# M0519AE_v1 register map
File version: 1.0
Registers are 32-bit, read-write, reset 0x0 unless marked. A register's access mark holds for its fields unless they carry their own. Offsets are from the block's base; [hi:lo] are bit positions; 'fields as' and 'values as' point back to an identical list.

## EPWM0 — EPWM Register Map
Base 0x40190000
Same registers: EPWM1 0x40194000
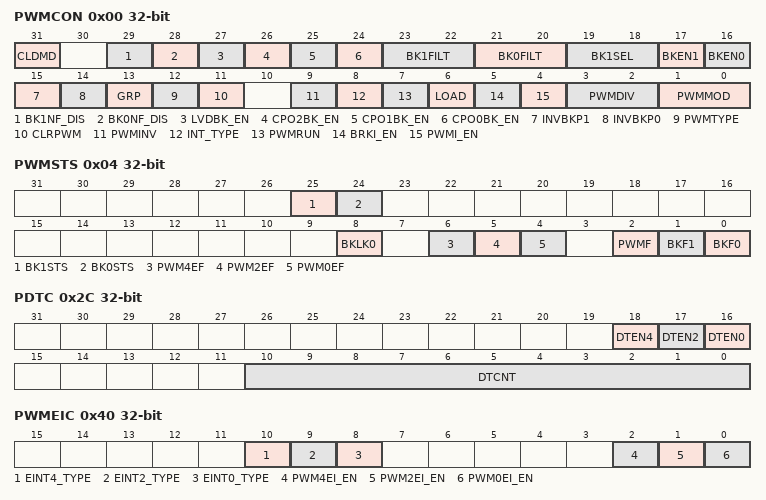
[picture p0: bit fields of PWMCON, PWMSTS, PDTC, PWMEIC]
0x00 PWMCON — EPWM Control Register
  [31] CLDMD — Center Reload Mode Enable Bit. This bit only works when EPWM operating in Center-aligned mode.
    0=EPWM reload duty register at the period point of PWM counter; 1=EPWM reload duty register at the center point of PWM counter
  [29] BK1NF_DIS — PWM Brake 1 Noise Filter Disable Bit
    0=Noise filter of PWM Brake 1 Enabled; 1=Noise filter of PWM Brake 1 Disabled
  [28] BK0NF_DIS — PWM Brake 0 Noise Filter Disable Bit
    0=Noise filter of PWM Brake 0 Enabled; 1=Noise filter of PWM Brake 0 Disabled
  [27] LVDBK_EN — Low-level Detection Trigger PWM Brake Function 1 Enable Bit
    0=Brake Function 1 triggered by Low-level detection Disabled; 1=Brake Function 1 triggered by Low-level detection Enabled
  [26] CPO2BK_EN — ACMP2 Digital Output As Brake 0 Source Enable Bit
    0=CO2 (ACMPSR[10]) as one brake source in Brake 0 Disabled; 1=CO2 (ACMPSR[10]) as one brake source in Brake 0 Enabled
  [25] CPO1BK_EN — ACMP1 Digital Output As Brake 0 Source Enable Bit
    0=CO1 (ACMPSR[9]) as one brake source in Brake 0 Disabled; 1=CO1 (ACMPSR[9]) as one brake source in Brake 0 Enabled
  [24] CPO0BK_EN — ACMP0 Digital Output As Brake0 Source Enable Bit
    0=CO0 (ACMPSR[8]) as one brake source in Brake 0 Disabled; 1=CO0 (ACMPSR[8]) as one brake source in Brake 0 Enabled
  [23:22] BK1FILT — Brake 1 (BKPx1 Pin) Edge Detector Filter Clock Selection
    0=filter clock is HCLK; 1=filter clock is HCLK/2; 2=filter clock is HCLK/4; 3=filter clock is HCLK/16
  [21:20] BK0FILT — Brake 0 (BKPx0 Pin) Edge Detector Filter Clock Selection
    values as BK1FILT
  [19:18] BK1SEL — Brake Function 1 Source Selection
    0=brake signal is from external pin EPWMx_BRAKE1 (x=0~1 for unit0~1); 1=brake signal is from analog comparator 0 output CO0 (ACMPSR[8]); 2=brake signal is from analog comparator 1 output CO1 (ACMPSR[9]); 3=brake signal is from analog comparator 2 output CO2 (ACMPSR[10])
  [17] BKEN1 — BRAKE1 Pin Trigger Brake Function 1 Enable Bit
    0=PWMx brake function 1 Disabled; 1=PWMx brake function 1 Enabled
  [16] BKEN0 — BRAKE0 Pin Trigger Brake Function 0 Enable Bit
    0=PWMx brake function 0 Disabled; 1=PWMx brake function 0 Enabled
  [15] INVBKP1 — Inverse Brake 1 Pin State
    0=The state of pin EPWMx_BRAKE1 is passed to the negative edge detector; 1=The inversed state of pin EPWMx_BRAKE1 is passed to the negative edge detector
  [14] INVBKP0 — Inverse Brake 0 Pin State
    0=The state of pin EPWMx_BRAKE0 is passed to the negative edge detector; 1=The inversed state of pin EPWMx_BRAKE0 is passed to the negative edge detector
  [13] GRP — Group Bit
    0=The signals timing of PWM_CH0, PWM_CH2 and PWM_CH4 are independent; 1=Unify the signals timing of PWM_CH0, PWM_CH2 and PWM_CH4 in the same phase which is controlled by PWM_CH0
  [12] PWMTYPE — PWM Aligned Type Selection Bit
    0=Edge-aligned type; 1=Center-aligned type
  [11] CLRPWM — Clear PWM Counter Control Bit. Note: It is automatically cleared by hardware.
    0=Ignored; 1=Clear 16-bit PWM counter to 0000H
  [9] PWMINV — Inverse PWM Comparator Output. When PWMINV is set to high the PWM comparator output signals will be inversed, therefore the PWM Duty (in percentage) is changed to (1-Duty) before PWMINV is set to high.
    0=Not inverse PWM comparator output; 1=Inverse PWM comparator output
  [8] INT_TYPE — PWM Interrupt Type Selection Bit. Note: This bit is effective when PWM is in Center-aligned mode only.
    0=PWMF will be set if PWM counter underflow; 1=PWMF will be set if PWM counter matches PWMP register
  [7] PWMRUN — Start PWMRUN Control Bit
    0=The PWM stops running; 1=The PWM counter starts running
  [6] LOAD — Reload PWM Period Registers (PWMP) and PWM Duty Registers (PWM0~4) Control Bit. Note: This bit is written by software, cleared by hardware, and always read as 0.
    0=No action if written with 0. The value of PWM period register (PWMP) and PWM duty registers (PWM0~PWM4) are not loaded to PWM counter and Comparator registers; 1=Hardware will update the value of PWM period register (PWMP) and PWM duty registers (PWM0~PWM4) to PWM Counter and Comparator register at the time of PWM Counter matches PWMP in Edge- and Center-aligned modes or at the time of PWM Counter down counts with underflow in Center-aligned mode
  [5] BRKI_EN — Brake0 and Brak1 Interrupt Enable Bit
    0=Flags BKF0 (PWMSTS[0]) and BKF1 (PWMSTS[1]) Disabled to trigger PWM interrupt; 1=Flags BKF0 (PWMSTS[0]) and BKF1 (PWMSTS[1]) Enabled to trigger PWM interrupt
  [4] PWMI_EN — PWM Interrupt Enable Bit
    0=Flag PWMF (PWMSTS[2]) Disabled to trigger PWM interrupt; 1=Flag PWMF (PWMSTS[2]) Enabled to trigger PWM interrupt
  [3:2] PWMDIV — PWM Clock Pre-divider Selection
    0=PWM clock is EPWMx_CLK; 1=PWM clock is EPWMx_CLK/2; 2=PWM clock is EPWMx_CLK/4; 3=PWM clock is EPWMx_CLK/16
  [1:0] PWMMOD — PWM Mode Selection
    0=PWM mode is independent mode; 1=PWM mode is pair/complementary mode; 2=PWM mode is synchronized mode
0x04 PWMSTS — EPWM Status Register
  [25] BK1STS ro — Brake 1 Status (Read Only)
    0=PWM had been out of Brake 1 state; 1=PWM is in Brake 1 state
  [24] BK0STS ro — Brake 0 Status (Read Only)
    0=PWM had been out of Brake 0 state; 1=PWM is in Brake 0 state
  [8] BKLK0 — PWM Brake 0 Locked. Note: This bit must be cleared by writing 1 to itself through software.
    0=Brake 0 state is released; 1=When PWM Brake detects a falling signal at EPWMx_BRAKE0, x=0, 1. This flag will be set to high to indicate the Brake 0 state is locked
  [6] PWM4EF — PWM Channel 4 Edge Flag. Note: This bit must be cleared by writing 1 to itself through software.
    0=PWM_CH4 not toggled; 1=Hardware will set this flag to high at the time of PWM_CH4 rising or falling. If EINT4_TYPE (PWMEIC[10]) = 0, this bit is set when PWM_CH4 falling is detected. If EINT4_TYPE (PWMEIC[10]) = 1, this bit is set when PWM_CH4 rising is detected
  [5] PWM2EF — PWM Channel 2 Edge Flag. Note: This bit must be cleared by writing 1 to itself through software.
    0=PWM_CH2 not toggled; 1=Hardware will set this flag to high at the time of PWM_CH2 rising or falling. If EINT2_TYPE (PWMEIC[9]) = 0, this bit is set when PWM_CH2 falling is detected. If EINT2_TYPE (PWMEIC[9]) = 1, this bit is set when PWM_CH2 rising is detected
  [4] PWM0EF — PWM Channel 0 Edge Flag. Note: This bit must be cleared by writing 1 to itself through software.
    0=PWM_CH0 not toggled; 1=Hardware will set this flag to high at the time of PWM_CH0 rising or falling. If EINT0_TYPE (PWMEIC[8]) = 0, this bit is set when PWM_CH0 falling is detected. If EINT0_TYPE (PWMEIC[8]) = 1, this bit is set when PWM_CH0 rising is detected
  [2] PWMF — PWM Period Flag. Note: This bit must be cleared by writing 1 to itself through software.
    0=The PWM Counter has not up counted to the value of PWMP or down counted with underflow; 1=Hardware will set this flag to high at the time of PWM Counter matches PWMP in Edge- and Center-aligned modes or at the time of PWM Counter down counts with underflow in Center-aligned mode
  [1] BKF1 — PWM Brake1 Flag. Note: This bit must be cleared by writing 1 to itself through software.
    0=PWM Brake 1 is able to poll falling signal at EPWMx_BRAKE1, x=0, 1 and has not recognized any one; 1=When PWM Brake 1 detects a falling signal at pin EPWMx_BRAKE1, x=0, 1, this flag will be set to high
  [0] BKF0 — PWM Brake0 Flag. Note: This bit must be cleared by writing 1 to itself through software.
    0=PWM Brake 0 is able to poll falling signal at EPWMx_BRAKE0, x=0, 1 and has not recognized any one; 1=When PWM Brake 0 detects a falling signal at EPWMx_BRAKE0, x=0, 1, this flag will be set to high
0x08 PWMP — EPWM Period Register
  [15:0] PWMP — PWM Period Register. Edge-aligned:
0x0C PWM0 — EPWM PWM0 Duty Register
  [15:0] PWM_Duty — PWM Duty Register. Edge-aligned:
0x10 PWM2 — EPWM PWM2 Duty Register
  [15:0] PWM_Duty — PWM Duty Register. Edge-aligned:
0x14 PWM4 — EPWM PWM4 Duty Register
  [15:0] PWM_Duty — PWM Duty Register. Edge-aligned:
0x18 PMSKE — EPWM Mask Mode Enable Register
  [5:0] PMSKE — PWM Mask Enable Bits. The PWM generator signal will be masked when this bit is enabled. The corresponding PWM channel n will be output with PMSKD[n] data.
    0=PWM generator signal is output to next stage; 1=PWM generator signal is masked and PMSKD[n] is output to next stage, n = 0~5
0x1C PMSKD — EPWM Mask Mode Data Register
  [5:0] PMSKD — PWM Mask Data Bit
    0=Output logic low to PWM_CHn; 1=Output logic high to PWM_CHn
0x2C PDTC — EPWM Dead-time Control Register
  [18] DTEN4 — Enable Dead-time Insertion for PWMx Pair (PWM_CH4, PWM_CH5). Dead-time insertion is only active when this pair of complementary PWM is enabled. If dead-time insertion is inactive, the outputs of pin pair are complementary without any delay.
    0=Dead-time insertion Disabled on the pin pair (PWM_CH4, PWM_CH5); 1=Dead-time insertion Enabled on the pin pair (PWM_CH4, PWM_CH5)
  [17] DTEN2 — Enable Dead-time Insertion for PWMx Pair (PWM_CH2, PWM_CH3). Dead-time insertion is only active when this pair of complementary PWM is enabled. If dead-time insertion is inactive, the outputs of pin pair are complementary without any delay.
    0=Dead-time insertion Disabled on the pin pair (PWM_CH2, PWM_CH3); 1=Dead-time insertion Enabled on the pin pair (PWM_CH2, PWM_CH3)
  [16] DTEN0 — Enable Dead-time Insertion for PWMx Pair (PWM_CH0, PWM_CH1). Dead-time insertion is only active when this pair of complementary PWM is enabled. If dead-time insertion is inactive, the outputs of pin pair are complementary without any delay.
    0=Dead-time insertion Disabled on the pin pair (PWM_CH0, PWM_CH1); 1=Dead-time insertion Enabled on the pin pair (PWM_CH0, PWM_CH1)
  [10:0] DTCNT — Dead-time Counter. The dead-time can be calculated according to the following formula:
0x30 PWMB — EPWM Brake Output Register
  [5:0] PWMB — PWM Brake Output
    0=PWM_CHn output before polarity control is low when Brake is asserted; 1=PWM_CHn output before polarity control is high when Brake is asserted
0x34 PNPC — EPWM Negative Polarity Control Register
  [5:0] PNP — PWM Negative Polarity Control
    0=PWM_CHn output is active high; 1=PWM_CHn output is active low
0x3C PWMFCNT — EPWMF Compared Counter Register
  [3:0] PWMFCNT — PWMF Compared Counter. The register sets the count number which defines how many times of PWM period occurs to set bit PWMF (PWMSTS[2]) to request the PWM period interrupt. PWMF (PWMSTS[2]) will be set in every (PWMFCNT[3:0] + 1) times of PWM period or center point defined by INT_TYPE at PWMCON[8] occurs
0x40 PWMEIC — EPWM Edge Interrupt Control Register
  [10] EINT4_TYPE — PWM Channel 4 Edge Interrupt Type
    0=PWM4EF will be set if falling edge is detected at PWM_CH4; 1=PWM4EF will be set if rising edge is detected at PWM_CH4
  [9] EINT2_TYPE — PWM Channel 2 Edge Interrupt Type
    0=PWM2EF will be set if falling edge is detected at PWM_CH2; 1=PWM2EF will be set if rising edge is detected at PWM_CH2
  [8] EINT0_TYPE — PWM Channel 0 Edge Interrupt Type
    0=PWM0EF will be set if falling edge is detected at PWM_CH0; 1=PWM0EF will be set if rising edge is detected at PWM_CH0
  [2] PWM4EI_EN — Enable PWM Channel 4 Edge Interrupt
    0=Flag PWM4EF Disabled to trigger PWM interrupt; 1=Flag PWM4EF Enabled to trigger PWM interrupt
  [1] PWM2EI_EN — Enable PWM Channel 2 Edge Interrupt
    0=Flag PWM2EF Disabled to trigger PWM interrupt; 1=Flag PWM2EF Enabled to trigger PWM interrupt
  [0] PWM0EI_EN — Enable PWM Channel 0 Edge Interrupt
    0=Flag PWM0EF Disabled to trigger PWM interrupt; 1=Flag PWM0EF Enabled to trigger PWM interrupt
